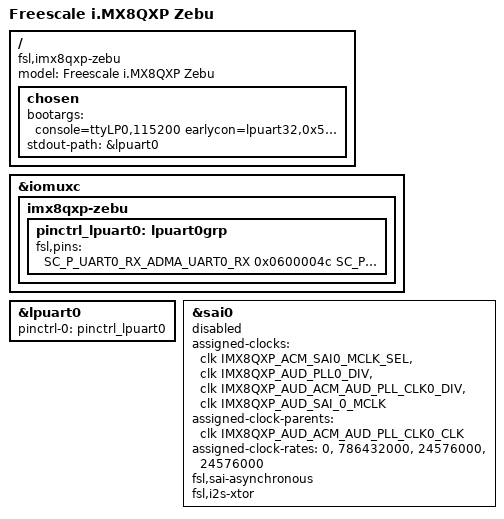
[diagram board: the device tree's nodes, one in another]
/*
 * Copyright (C) 2016 Freescale Semiconductor, Inc.
 * Copyright 2017 NXP
 *
 * This program is free software; you can redistribute it and/or
 * modify it under the terms of the GNU General Public License
 * as published by the Free Software Foundation; either version 2
 * of the License, or (at your option) any later version.
 *
 * This program is distributed in the hope that it will be useful,
 * but WITHOUT ANY WARRANTY; without even the implied warranty of
 * MERCHANTABILITY or FITNESS FOR A PARTICULAR PURPOSE.  See the
 * GNU General Public License for more details.
 */

/dts-v1/;

/* First 128KB is for PSCI ATF. */
/memreserve/ 0x80000000 0x00020000;

#include "fsl-imx8qxp.dtsi"

/ {
	model = "Freescale i.MX8QXP Zebu";
	compatible = "fsl,imx8qxp-zebu", "fsl,imx8qxp";

	chosen {
		bootargs = "console=ttyLP0,115200 earlycon=lpuart32,0x5a060000,115200";
		stdout-path = &lpuart0;
	};
};

&iomuxc {
	imx8qxp-zebu {

		pinctrl_lpuart0: lpuart0grp {
			fsl,pins = <
				SC_P_UART0_RX_ADMA_UART0_RX	0x0600004c
				SC_P_UART0_TX_ADMA_UART0_TX	0x0600004c
			>;
		};
	};
};

&lpuart0 { /* console */
	pinctrl-names = "default";
	pinctrl-0 = <&pinctrl_lpuart0>;
	status = "okay";
};

&sai0 {
	assigned-clocks = <&clk IMX8QXP_ACM_SAI0_MCLK_SEL>,
			<&clk IMX8QXP_AUD_PLL0_DIV>,
			<&clk IMX8QXP_AUD_ACM_AUD_PLL_CLK0_DIV>,
			<&clk IMX8QXP_AUD_SAI_0_MCLK>;
	assigned-clock-parents = <&clk IMX8QXP_AUD_ACM_AUD_PLL_CLK0_CLK>;
	assigned-clock-rates = <0>, <786432000>, <24576000>, <24576000>;
	fsl,sai-asynchronous;
	fsl,i2s-xtor;
	status = "disabled";
};

